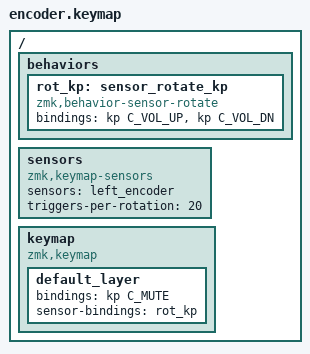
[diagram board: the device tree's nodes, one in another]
/*
 * Copyright (c) 2022 The ZMK Contributors
 *
 * SPDX-License-Identifier: MIT
 */

#include <behaviors.dtsi>
#include <dt-bindings/zmk/keys.h>
#include <dt-bindings/zmk/bt.h>

/ {
    behaviors {
        rot_kp: sensor_rotate_kp {
            compatible = "zmk,behavior-sensor-rotate";
            #sensor-binding-cells = <0>;
            bindings = <&kp C_VOL_UP &kp C_VOL_DN>;
        };
    };

    sensors: sensors {
        compatible = "zmk,keymap-sensors";
        sensors = <&left_encoder>;
        triggers-per-rotation = <20>;
    };

    keymap {
        compatible = "zmk,keymap";

        default_layer {
            bindings = <
                &kp C_MUTE
            >;

            sensor-bindings = <&rot_kp>;
        };
    };
};
